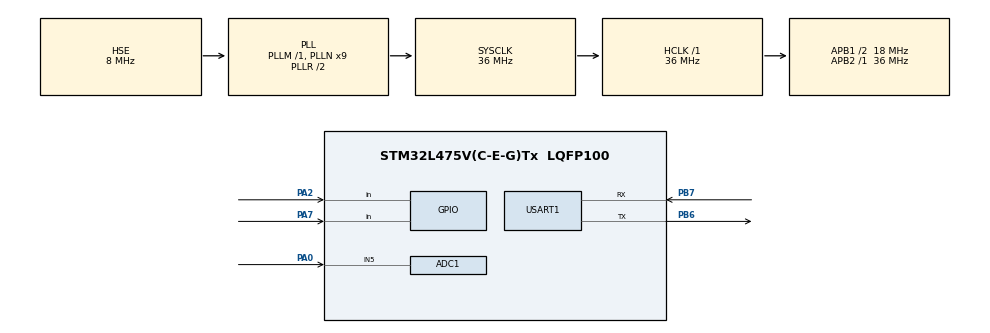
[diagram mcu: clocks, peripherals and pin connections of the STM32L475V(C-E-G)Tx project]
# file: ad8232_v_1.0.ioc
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ADC1.Channel-3\#ChannelRegularConversion=ADC_CHANNEL_5
ADC1.ContinuousConvMode=ENABLE
ADC1.NbrOfConversionFlag=1
ADC1.OffsetNumber-3\#ChannelRegularConversion=ADC_OFFSET_NONE
ADC1.Rank-3\#ChannelRegularConversion=1
ADC1.Resolution=ADC_RESOLUTION_10B
ADC1.SamplingTime-3\#ChannelRegularConversion=ADC_SAMPLETIME_2CYCLES_5
ADC1.master=1
Mcu.Family=STM32L4
Mcu.Name=STM32L475V(C-E-G)Tx
Mcu.Package=LQFP100
NVIC.PriorityGroup=NVIC_PRIORITYGROUP_4
PA0.Signal=ADCx_IN5
PA13\ (JTMS-SWDIO).Mode=Serial_Wire
PA13\ (JTMS-SWDIO).Signal=SYS_JTMS-SWDIO
PA14\ (JTCK-SWCLK).Mode=Serial_Wire
PA14\ (JTCK-SWCLK).Signal=SYS_JTCK-SWCLK
PA2.Signal=GPIO_Input
PA7.Signal=GPIO_Input
PB6.Mode=Asynchronous
PB6.Signal=USART1_TX
PB7.Mode=Asynchronous
PB7.Signal=USART1_RX
PH0-OSC_IN\ (PH0).Mode=HSE-External-Oscillator
PH0-OSC_IN\ (PH0).Signal=RCC_OSC_IN
PH1-OSC_OUT\ (PH1).Mode=HSE-External-Oscillator
PH1-OSC_OUT\ (PH1).Signal=RCC_OSC_OUT
ProjectManager.HeapSize=0x200
ProjectManager.StackSize=0x400
ProjectManager.TargetToolchain=STM32CubeIDE
RCC.ADCFreq_Value=32000000
RCC.AHBFreq_Value=36000000
RCC.APB1CLKDivider=RCC_HCLK_DIV2
RCC.APB1Freq_Value=18000000
RCC.APB1TimFreq_Value=36000000
RCC.APB2Freq_Value=36000000
RCC.APB2TimFreq_Value=36000000
RCC.CortexFreq_Value=36000000
RCC.HCLKFreq_Value=36000000
RCC.HSE_VALUE=8000000
RCC.HSI_VALUE=16000000
RCC.LSE_VALUE=32768
RCC.MSI_VALUE=4000000
RCC.PLLN=9
RCC.PLLSourceVirtual=RCC_PLLSOURCE_HSE
RCC.SYSCLKFreq_VALUE=36000000
RCC.SYSCLKSource=RCC_SYSCLKSOURCE_PLLCLK
RCC.USBFreq_Value=32000000
RCC.VCOOutputFreq_Value=72000000
SH.ADCx_IN5.0=ADC1_IN5,IN5-Single-Ended
USART1.VirtualMode-Asynchronous=VM_ASYNC
board=custom

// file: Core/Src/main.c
/* USER CODE BEGIN Header */
/**
 ******************************************************************************
 * @file           : main.c
 * @brief          : Main program body
 ******************************************************************************
 * @attention
 *
 * <h2><center>&copy; Copyright (c) 2021 STMicroelectronics.
 * All rights reserved.</center></h2>
 *
 * This software component is licensed by ST under Ultimate Liberty license
 * SLA0044, the "License"; You may not use this file except in compliance with
 * the License. You may obtain a copy of the License at:
 *                             www.st.com/SLA0044
 *
 ******************************************************************************
 */
/* USER CODE END Header */
#include "main.h"

/* USER CODE BEGIN Includes */
#include <string.h>
#include <stdio.h>
#include <retarget.h>
/* USER CODE END Includes */

ADC_HandleTypeDef hadc1;

UART_HandleTypeDef huart1;

void SystemClock_Config(void);
static void MX_GPIO_Init(void);
static void MX_USART1_UART_Init(void);
static void MX_ADC1_Init(void);

int main(void)
{
  /* USER CODE BEGIN 1 */
//	uint16_t raw;
	int val;
  /* USER CODE END 1 */

  /* MCU Configuration--------------------------------------------------------*/

  /* Reset of all peripherals, Initializes the Flash interface and the Systick. */
  HAL_Init();

  /* Configure the system clock */
  SystemClock_Config();

  /* Initialize all configured peripherals */
  MX_GPIO_Init();
  MX_USART1_UART_Init();
  MX_ADC1_Init();
  /* USER CODE BEGIN 2 */
	RetargetInit(&huart1);

  /* USER CODE END 2 */

  /* Infinite loop */
  /* USER CODE BEGIN WHILE */
	printf("Printing\n");
	while (1)
	{
    /* USER CODE END WHILE */

    /* USER CODE BEGIN 3 */
		HAL_ADC_Start(&hadc1);
		HAL_ADC_PollForConversion(&hadc1, HAL_MAX_DELAY);
		val = HAL_ADC_GetValue(&hadc1);
		HAL_ADC_Stop(&hadc1);

		printf("%d\n",val);

//		printf("\r\nPA_2 %d", HAL_GPIO_ReadPin(GPIOA, GPIO_PIN_2));
//		printf("\r\nPA_7 %d", HAL_GPIO_ReadPin(GPIOA, GPIO_PIN_7));
		HAL_Delay(100);

	}
  /* USER CODE END 3 */
}

void SystemClock_Config(void)
{
  RCC_OscInitTypeDef RCC_OscInitStruct = {0};
  RCC_ClkInitTypeDef RCC_ClkInitStruct = {0};
  RCC_PeriphCLKInitTypeDef PeriphClkInit = {0};

  /** Initializes the RCC Oscillators according to the specified parameters
  * in the RCC_OscInitTypeDef structure.
  */
  RCC_OscInitStruct.OscillatorType = RCC_OSCILLATORTYPE_HSE;
  RCC_OscInitStruct.HSEState = RCC_HSE_ON;
  RCC_OscInitStruct.PLL.PLLState = RCC_PLL_ON;
  RCC_OscInitStruct.PLL.PLLSource = RCC_PLLSOURCE_HSE;
  RCC_OscInitStruct.PLL.PLLM = 1;
  RCC_OscInitStruct.PLL.PLLN = 9;
  RCC_OscInitStruct.PLL.PLLP = RCC_PLLP_DIV7;
  RCC_OscInitStruct.PLL.PLLQ = RCC_PLLQ_DIV2;
  RCC_OscInitStruct.PLL.PLLR = RCC_PLLR_DIV2;
  if (HAL_RCC_OscConfig(&RCC_OscInitStruct) != HAL_OK)
  {
    Error_Handler();
  }
  /** Initializes the CPU, AHB and APB buses clocks
  */
  RCC_ClkInitStruct.ClockType = RCC_CLOCKTYPE_HCLK|RCC_CLOCKTYPE_SYSCLK
                              |RCC_CLOCKTYPE_PCLK1|RCC_CLOCKTYPE_PCLK2;
  RCC_ClkInitStruct.SYSCLKSource = RCC_SYSCLKSOURCE_PLLCLK;
  RCC_ClkInitStruct.AHBCLKDivider = RCC_SYSCLK_DIV1;
  RCC_ClkInitStruct.APB1CLKDivider = RCC_HCLK_DIV2;
  RCC_ClkInitStruct.APB2CLKDivider = RCC_HCLK_DIV1;

  if (HAL_RCC_ClockConfig(&RCC_ClkInitStruct, FLASH_LATENCY_2) != HAL_OK)
  {
    Error_Handler();
  }
  PeriphClkInit.PeriphClockSelection = RCC_PERIPHCLK_USART1|RCC_PERIPHCLK_ADC;
  PeriphClkInit.Usart1ClockSelection = RCC_USART1CLKSOURCE_PCLK2;
  PeriphClkInit.AdcClockSelection = RCC_ADCCLKSOURCE_PLLSAI1;
  PeriphClkInit.PLLSAI1.PLLSAI1Source = RCC_PLLSOURCE_HSE;
  PeriphClkInit.PLLSAI1.PLLSAI1M = 1;
  PeriphClkInit.PLLSAI1.PLLSAI1N = 8;
  PeriphClkInit.PLLSAI1.PLLSAI1P = RCC_PLLP_DIV7;
  PeriphClkInit.PLLSAI1.PLLSAI1Q = RCC_PLLQ_DIV2;
  PeriphClkInit.PLLSAI1.PLLSAI1R = RCC_PLLR_DIV2;
  PeriphClkInit.PLLSAI1.PLLSAI1ClockOut = RCC_PLLSAI1_ADC1CLK;
  if (HAL_RCCEx_PeriphCLKConfig(&PeriphClkInit) != HAL_OK)
  {
    Error_Handler();
  }
  /** Configure the main internal regulator output voltage
  */
  if (HAL_PWREx_ControlVoltageScaling(PWR_REGULATOR_VOLTAGE_SCALE1) != HAL_OK)
  {
    Error_Handler();
  }
}

static void MX_ADC1_Init(void)
{

  ADC_MultiModeTypeDef multimode = {0};
  ADC_ChannelConfTypeDef sConfig = {0};

  /** Common config
  */
  hadc1.Instance = ADC1;
  hadc1.Init.ClockPrescaler = ADC_CLOCK_ASYNC_DIV1;
  hadc1.Init.Resolution = ADC_RESOLUTION_10B;
  hadc1.Init.DataAlign = ADC_DATAALIGN_RIGHT;
  hadc1.Init.ScanConvMode = ADC_SCAN_DISABLE;
  hadc1.Init.EOCSelection = ADC_EOC_SINGLE_CONV;
  hadc1.Init.LowPowerAutoWait = DISABLE;
  hadc1.Init.ContinuousConvMode = ENABLE;
  hadc1.Init.NbrOfConversion = 1;
  hadc1.Init.DiscontinuousConvMode = DISABLE;
  hadc1.Init.ExternalTrigConv = ADC_SOFTWARE_START;
  hadc1.Init.ExternalTrigConvEdge = ADC_EXTERNALTRIGCONVEDGE_NONE;
  hadc1.Init.DMAContinuousRequests = DISABLE;
  hadc1.Init.Overrun = ADC_OVR_DATA_PRESERVED;
  hadc1.Init.OversamplingMode = DISABLE;
  if (HAL_ADC_Init(&hadc1) != HAL_OK)
  {
    Error_Handler();
  }
  /** Configure the ADC multi-mode
  */
  multimode.Mode = ADC_MODE_INDEPENDENT;
  if (HAL_ADCEx_MultiModeConfigChannel(&hadc1, &multimode) != HAL_OK)
  {
    Error_Handler();
  }
  /** Configure Regular Channel
  */
  sConfig.Channel = ADC_CHANNEL_5;
  sConfig.Rank = ADC_REGULAR_RANK_1;
  sConfig.SamplingTime = ADC_SAMPLETIME_2CYCLES_5;
  sConfig.SingleDiff = ADC_SINGLE_ENDED;
  sConfig.OffsetNumber = ADC_OFFSET_NONE;
  sConfig.Offset = 0;
  if (HAL_ADC_ConfigChannel(&hadc1, &sConfig) != HAL_OK)
  {
    Error_Handler();
  }

}

static void MX_USART1_UART_Init(void)
{

  huart1.Instance = USART1;
  huart1.Init.BaudRate = 115200;
  huart1.Init.WordLength = UART_WORDLENGTH_8B;
  huart1.Init.StopBits = UART_STOPBITS_1;
  huart1.Init.Parity = UART_PARITY_NONE;
  huart1.Init.Mode = UART_MODE_TX_RX;
  huart1.Init.HwFlowCtl = UART_HWCONTROL_NONE;
  huart1.Init.OverSampling = UART_OVERSAMPLING_16;
  huart1.Init.OneBitSampling = UART_ONE_BIT_SAMPLE_DISABLE;
  huart1.AdvancedInit.AdvFeatureInit = UART_ADVFEATURE_NO_INIT;
  if (HAL_UART_Init(&huart1) != HAL_OK)
  {
    Error_Handler();
  }

}

static void MX_GPIO_Init(void)
{
  GPIO_InitTypeDef GPIO_InitStruct = {0};

  /* GPIO Ports Clock Enable */
  __HAL_RCC_GPIOH_CLK_ENABLE();
  __HAL_RCC_GPIOA_CLK_ENABLE();
  __HAL_RCC_GPIOB_CLK_ENABLE();

  /*Configure GPIO pins : PA2 PA7 */
  GPIO_InitStruct.Pin = GPIO_PIN_2|GPIO_PIN_7;
  GPIO_InitStruct.Mode = GPIO_MODE_INPUT;
  GPIO_InitStruct.Pull = GPIO_NOPULL;
  HAL_GPIO_Init(GPIOA, &GPIO_InitStruct);

}

void Error_Handler(void)
{
}

/************************ (C) COPYRIGHT STMicroelectronics *****END OF FILE****/
